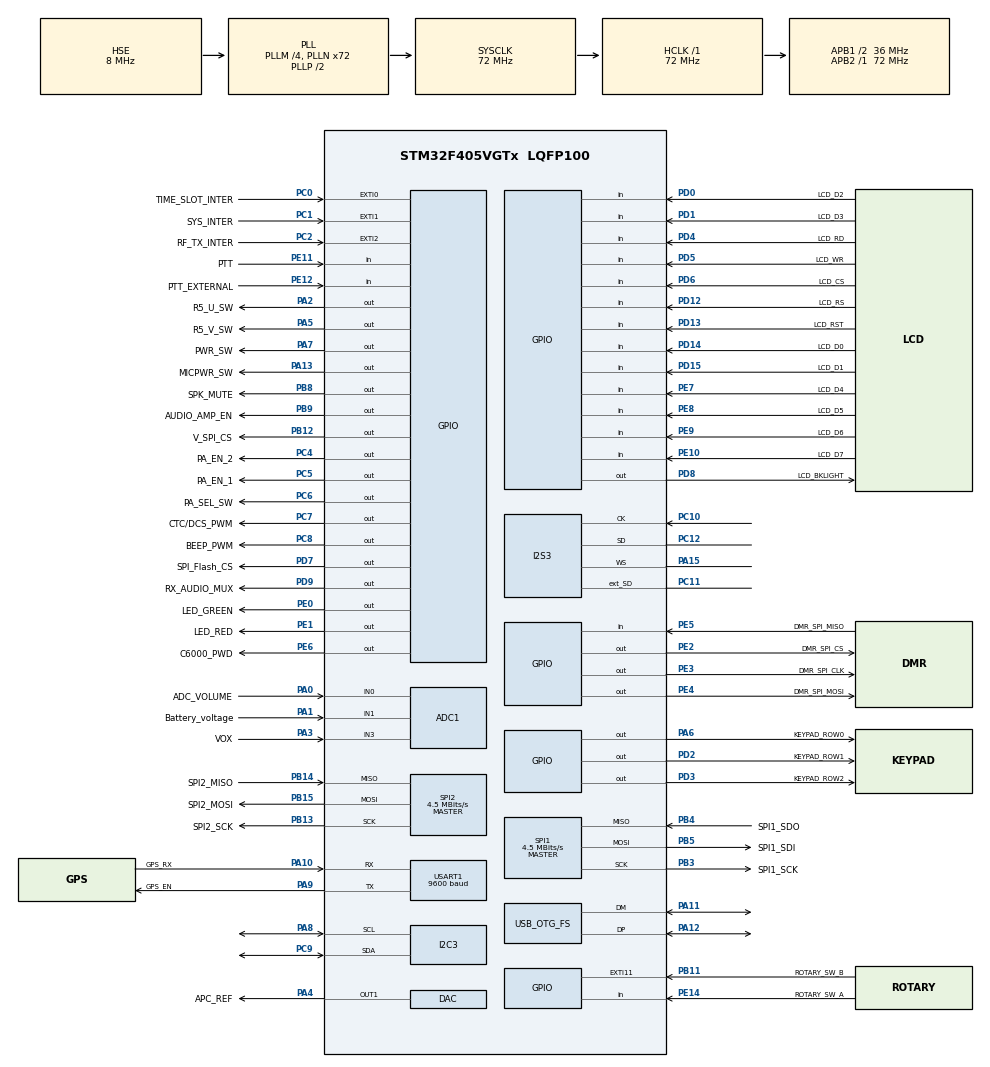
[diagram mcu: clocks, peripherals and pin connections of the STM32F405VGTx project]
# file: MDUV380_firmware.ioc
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ADC1.Channel-0\#ChannelRegularConversion=ADC_CHANNEL_0
ADC1.Channel-1\#ChannelRegularConversion=ADC_CHANNEL_1
ADC1.Channel-2\#ChannelRegularConversion=ADC_CHANNEL_3
ADC1.Channel-3\#ChannelRegularConversion=ADC_CHANNEL_TEMPSENSOR
ADC1.ClockPrescaler=ADC_CLOCK_SYNC_PCLK_DIV8
ADC1.ContinuousConvMode=DISABLE
ADC1.DMAContinuousRequests=ENABLE
ADC1.DiscontinuousConvMode=DISABLE
ADC1.ExternalTrigConv=ADC_EXTERNALTRIGCONV_T3_TRGO
ADC1.InjNumberOfConversion=0
ADC1.NbrOfConversion=4
ADC1.NbrOfConversionFlag=1
ADC1.Rank-0\#ChannelRegularConversion=1
ADC1.Rank-1\#ChannelRegularConversion=2
ADC1.Rank-2\#ChannelRegularConversion=3
ADC1.Rank-3\#ChannelRegularConversion=4
ADC1.SamplingTime-0\#ChannelRegularConversion=ADC_SAMPLETIME_480CYCLES
ADC1.SamplingTime-1\#ChannelRegularConversion=ADC_SAMPLETIME_480CYCLES
ADC1.SamplingTime-2\#ChannelRegularConversion=ADC_SAMPLETIME_480CYCLES
ADC1.SamplingTime-3\#ChannelRegularConversion=ADC_SAMPLETIME_480CYCLES
ADC1.ScanConvMode=ENABLE
ADC1.master=1
Dma.ADC1.5.Direction=DMA_PERIPH_TO_MEMORY
Dma.ADC1.5.FIFOMode=DMA_FIFOMODE_DISABLE
Dma.ADC1.5.Instance=DMA2_Stream4
Dma.ADC1.5.MemDataAlignment=DMA_MDATAALIGN_HALFWORD
Dma.ADC1.5.MemInc=DMA_MINC_ENABLE
Dma.ADC1.5.Mode=DMA_CIRCULAR
Dma.ADC1.5.PeriphDataAlignment=DMA_PDATAALIGN_HALFWORD
Dma.ADC1.5.PeriphInc=DMA_PINC_DISABLE
Dma.ADC1.5.Priority=DMA_PRIORITY_LOW
Dma.I2S3_EXT_TX.0.Direction=DMA_MEMORY_TO_PERIPH
Dma.I2S3_EXT_TX.0.FIFOMode=DMA_FIFOMODE_DISABLE
Dma.I2S3_EXT_TX.0.Instance=DMA1_Stream5
Dma.I2S3_EXT_TX.0.MemDataAlignment=DMA_MDATAALIGN_HALFWORD
Dma.I2S3_EXT_TX.0.MemInc=DMA_MINC_ENABLE
Dma.I2S3_EXT_TX.0.Mode=DMA_CIRCULAR
Dma.I2S3_EXT_TX.0.PeriphDataAlignment=DMA_PDATAALIGN_HALFWORD
Dma.I2S3_EXT_TX.0.PeriphInc=DMA_PINC_DISABLE
Dma.I2S3_EXT_TX.0.Priority=DMA_PRIORITY_LOW
Dma.MEMTOMEM.3.Direction=DMA_MEMORY_TO_MEMORY
Dma.MEMTOMEM.3.FIFOMode=DMA_FIFOMODE_ENABLE
Dma.MEMTOMEM.3.FIFOThreshold=DMA_FIFO_THRESHOLD_FULL
Dma.MEMTOMEM.3.Instance=DMA2_Stream0
Dma.MEMTOMEM.3.MemBurst=DMA_MBURST_SINGLE
Dma.MEMTOMEM.3.MemDataAlignment=DMA_MDATAALIGN_BYTE
Dma.MEMTOMEM.3.MemInc=DMA_MINC_DISABLE
Dma.MEMTOMEM.3.Mode=DMA_NORMAL
Dma.MEMTOMEM.3.PeriphBurst=DMA_PBURST_SINGLE
Dma.MEMTOMEM.3.PeriphDataAlignment=DMA_PDATAALIGN_BYTE
Dma.MEMTOMEM.3.PeriphInc=DMA_PINC_ENABLE
Dma.MEMTOMEM.3.Priority=DMA_PRIORITY_LOW
Dma.Request0=I2S3_EXT_TX
Dma.Request1=SPI3_RX
Dma.Request2=USART1_RX
Dma.Request3=MEMTOMEM
Dma.Request4=TIM1_CH1
Dma.Request5=ADC1
Dma.SPI3_RX.1.Direction=DMA_PERIPH_TO_MEMORY
Dma.SPI3_RX.1.FIFOMode=DMA_FIFOMODE_DISABLE
Dma.SPI3_RX.1.Instance=DMA1_Stream0
Dma.SPI3_RX.1.MemDataAlignment=DMA_MDATAALIGN_HALFWORD
Dma.SPI3_RX.1.MemInc=DMA_MINC_ENABLE
Dma.SPI3_RX.1.Mode=DMA_CIRCULAR
Dma.SPI3_RX.1.PeriphDataAlignment=DMA_PDATAALIGN_HALFWORD
Dma.SPI3_RX.1.PeriphInc=DMA_PINC_DISABLE
Dma.SPI3_RX.1.Priority=DMA_PRIORITY_LOW
Dma.TIM1_CH1.4.Direction=DMA_MEMORY_TO_PERIPH
Dma.TIM1_CH1.4.FIFOMode=DMA_FIFOMODE_DISABLE
Dma.TIM1_CH1.4.Instance=DMA2_Stream1
Dma.TIM1_CH1.4.MemDataAlignment=DMA_MDATAALIGN_WORD
Dma.TIM1_CH1.4.MemInc=DMA_MINC_ENABLE
Dma.TIM1_CH1.4.Mode=DMA_CIRCULAR
Dma.TIM1_CH1.4.PeriphDataAlignment=DMA_PDATAALIGN_WORD
Dma.TIM1_CH1.4.PeriphInc=DMA_PINC_DISABLE
Dma.TIM1_CH1.4.Priority=DMA_PRIORITY_HIGH
Dma.USART1_RX.2.Direction=DMA_PERIPH_TO_MEMORY
Dma.USART1_RX.2.FIFOMode=DMA_FIFOMODE_DISABLE
Dma.USART1_RX.2.Instance=DMA2_Stream2
Dma.USART1_RX.2.MemDataAlignment=DMA_MDATAALIGN_BYTE
Dma.USART1_RX.2.MemInc=DMA_MINC_ENABLE
Dma.USART1_RX.2.Mode=DMA_CIRCULAR
Dma.USART1_RX.2.PeriphDataAlignment=DMA_PDATAALIGN_BYTE
Dma.USART1_RX.2.PeriphInc=DMA_PINC_DISABLE
Dma.USART1_RX.2.Priority=DMA_PRIORITY_LOW
FREERTOS.Tasks01=defaultTask,24,2048,StartDefaultTask,Default,NULL,Dynamic,NULL,NULL
FREERTOS.configLIBRARY_MAX_SYSCALL_INTERRUPT_PRIORITY=5
FREERTOS.configTIMER_TASK_PRIORITY=55
FREERTOS.configTOTAL_HEAP_SIZE=20480
FREERTOS.configUSE_NEWLIB_REENTRANT=1
I2C3.I2C_Mode=I2C_Fast
I2S3.AudioFreq=I2S_AUDIOFREQ_8K
I2S3.CPOL=I2S_CPOL_HIGH
I2S3.DataFormat=I2S_DATAFORMAT_16B_EXTENDED
I2S3.ErrorAudioFreq=-0.27 %
I2S3.FullDuplexMode=I2S_FULLDUPLEXMODE_ENABLE
I2S3.Instance=SPI$Index
I2S3.Mode=I2S_MODE_SLAVE_RX
I2S3.RealAudioFreq=7.978 KHz
I2S3.Standard=I2S_STANDARD_PHILIPS
I2S3.VirtualMode=I2S_MODE_SLAVE
Mcu.Family=STM32F4
Mcu.Name=STM32F405VGTx
Mcu.Package=LQFP100
NVIC.DMA1_Stream0_IRQn=true\:6\:0\:true\:false\:true\:true\:false\:true\:true
NVIC.DMA1_Stream5_IRQn=true\:6\:0\:true\:false\:true\:true\:false\:true\:true
NVIC.DMA2_Stream1_IRQn=true\:15\:0\:true\:false\:true\:true\:false\:true\:true
NVIC.DMA2_Stream2_IRQn=true\:15\:0\:true\:false\:true\:true\:false\:true\:true
NVIC.DMA2_Stream4_IRQn=true\:15\:0\:true\:false\:true\:true\:false\:true\:true
NVIC.EXTI0_IRQn=true\:5\:0\:false\:false\:true\:true\:true\:true\:true
NVIC.EXTI15_10_IRQn=true\:6\:0\:true\:false\:true\:true\:true\:true\:true
NVIC.EXTI1_IRQn=true\:5\:0\:false\:false\:true\:true\:true\:true\:true
NVIC.EXTI2_IRQn=true\:5\:0\:false\:false\:true\:true\:true\:true\:true
NVIC.OTG_FS_IRQn=true\:6\:0\:true\:false\:true\:true\:false\:true\:true
NVIC.PriorityGroup=NVIC_PRIORITYGROUP_4
NVIC.TIM8_TRG_COM_TIM14_IRQn=true\:4\:0\:true\:false\:true\:false\:false\:true\:true
NVIC.TimeBase=TIM8_TRG_COM_TIM14_IRQn
NVIC.TimeBaseIP=TIM14
NVIC.USART1_IRQn=true\:6\:0\:true\:false\:true\:true\:true\:true\:true
PA0-WKUP.GPIO_Label=ADC_VOLUME
PA0-WKUP.Signal=ADCx_IN0
PA1.GPIO_Label=Battery_voltage
PA1.Signal=ADCx_IN1
PA10.GPIO_Label=GPS_RX
PA10.Mode=Asynchronous
PA10.Signal=USART1_RX
PA11.Mode=Device_Only
PA11.Signal=USB_OTG_FS_DM
PA12.Mode=Device_Only
PA12.Signal=USB_OTG_FS_DP
PA13.GPIO_Label=MICPWR_SW
PA13.Signal=GPIO_Output
PA14.Signal=SYS_JTCK-SWCLK
PA15.Mode=Full_Duplex_Slave
PA15.Signal=I2S3_WS
PA2.GPIO_Label=R5_U_SW
PA2.Signal=GPIO_Output
PA3.GPIO_Label=VOX
PA3.Signal=ADCx_IN3
PA4.GPIO_Label=APC_REF
PA4.Signal=COMP_DAC1_group
PA5.GPIO_Label=R5_V_SW
PA5.Signal=GPIO_Output
PA6.GPIO_Label=KEYPAD_ROW0
PA6.Signal=GPIO_Output
PA7.GPIO_Label=PWR_SW
PA7.Signal=GPIO_Output
PA8.Mode=I2C
PA8.Signal=I2C3_SCL
PA9.GPIO_Label=GPS_EN
PA9.Mode=Asynchronous
PA9.Signal=USART1_TX
PB11.GPIO_Label=ROTARY_SW_B
PB11.GPIO_ModeDefaultEXTI=GPIO_MODE_IT_RISING_FALLING
PB11.GPIO_PuPd=GPIO_PULLUP
PB11.Signal=GPXTI11
PB12.GPIO_Label=V_SPI_CS
PB12.PinState=GPIO_PIN_SET
PB12.Signal=GPIO_Output
PB13.GPIO_Label=SPI2_SCK
PB13.Mode=Full_Duplex_Master
PB13.Signal=SPI2_SCK
PB14.GPIO_Label=SPI2_MISO
PB14.Mode=Full_Duplex_Master
PB14.Signal=SPI2_MISO
PB15.GPIO_Label=SPI2_MOSI
PB15.Mode=Full_Duplex_Master
PB15.Signal=SPI2_MOSI
PB3.GPIO_Label=SPI1_SCK
PB3.Mode=Full_Duplex_Master
PB3.Signal=SPI1_SCK
PB4.GPIO_Label=SPI1_SDO
PB4.Mode=Full_Duplex_Master
PB4.Signal=SPI1_MISO
PB5.GPIO_Label=SPI1_SDI
PB5.Mode=Full_Duplex_Master
PB5.Signal=SPI1_MOSI
PB8.GPIO_Label=SPK_MUTE
PB8.PinState=GPIO_PIN_SET
PB8.Signal=GPIO_Output
PB9.GPIO_Label=AUDIO_AMP_EN
PB9.PinState=GPIO_PIN_SET
PB9.Signal=GPIO_Output
PC0.GPIO_Label=TIME_SLOT_INTER
PC0.GPIO_ModeDefaultEXTI=GPIO_MODE_IT_FALLING
PC0.Signal=GPXTI0
PC1.GPIO_Label=SYS_INTER
PC1.GPIO_ModeDefaultEXTI=GPIO_MODE_IT_FALLING
PC1.Signal=GPXTI1
PC10.Mode=Full_Duplex_Slave
PC10.Signal=I2S3_CK
PC11.Mode=Full_Duplex_Slave
PC11.Signal=I2S3_ext_SD
PC12.Mode=Full_Duplex_Slave
PC12.Signal=I2S3_SD
PC14-OSC32_IN.Mode=LSE-External-Oscillator
PC14-OSC32_IN.Signal=RCC_OSC32_IN
PC15-OSC32_OUT.Mode=LSE-External-Oscillator
PC15-OSC32_OUT.Signal=RCC_OSC32_OUT
PC2.GPIO_Label=RF_TX_INTER
PC2.GPIO_ModeDefaultEXTI=GPIO_MODE_IT_FALLING
PC2.Signal=GPXTI2
PC4.GPIO_Label=PA_EN_2
PC4.Signal=GPIO_Output
PC5.GPIO_Label=PA_EN_1
PC5.Signal=GPIO_Output
PC6.GPIO_Label=PA_SEL_SW
PC6.Signal=GPIO_Output
PC7.GPIO_Label=CTC/DCS_PWM
PC7.GPIO_ModeDefaultOutputPP=GPIO_MODE_OUTPUT_OD
PC7.PinState=GPIO_PIN_SET
PC7.Signal=GPIO_Output
PC8.GPIO_Label=BEEP_PWM
PC8.Signal=GPIO_Output
PC9.Mode=I2C
PC9.Signal=I2C3_SDA
PD0.GPIO_Label=LCD_D2
PD0.GPIO_PuPd=GPIO_PULLDOWN
PD0.Signal=GPIO_Input
PD1.GPIO_Label=LCD_D3
PD1.GPIO_PuPd=GPIO_PULLDOWN
PD1.Signal=GPIO_Input
PD12.GPIO_Label=LCD_RS
PD12.Signal=GPIO_Input
PD13.GPIO_Label=LCD_RST
PD13.Signal=GPIO_Input
PD14.GPIO_Label=LCD_D0
PD14.GPIO_PuPd=GPIO_PULLDOWN
PD14.Signal=GPIO_Input
PD15.GPIO_Label=LCD_D1
PD15.GPIO_PuPd=GPIO_PULLDOWN
PD15.Signal=GPIO_Input
PD2.GPIO_Label=KEYPAD_ROW1
PD2.Signal=GPIO_Output
PD3.GPIO_Label=KEYPAD_ROW2
PD3.Signal=GPIO_Output
PD4.GPIO_Label=LCD_RD
PD4.Signal=GPIO_Input
PD5.GPIO_Label=LCD_WR
PD5.Signal=GPIO_Input
PD6.GPIO_Label=LCD_CS
PD6.Signal=GPIO_Input
PD7.GPIO_Label=SPI_Flash_CS
PD7.GPIO_Speed=GPIO_SPEED_FREQ_LOW
PD7.PinState=GPIO_PIN_SET
PD7.Signal=GPIO_Output
PD8.GPIO_Label=LCD_BKLIGHT
PD8.Signal=GPIO_Output
PD9.GPIO_Label=RX_AUDIO_MUX
PD9.PinState=GPIO_PIN_SET
PD9.Signal=GPIO_Output
PE0.GPIO_Label=LED_GREEN
PE0.Signal=GPIO_Output
PE1.GPIO_Label=LED_RED
PE1.Signal=GPIO_Output
PE10.GPIO_Label=LCD_D7
PE10.GPIO_PuPd=GPIO_PULLDOWN
PE10.Signal=GPIO_Input
PE11.GPIO_Label=PTT
PE11.GPIO_PuPd=GPIO_PULLUP
PE11.Signal=GPIO_Input
PE12.GPIO_Label=PTT_EXTERNAL
PE12.GPIO_PuPd=GPIO_PULLUP
PE12.Signal=GPIO_Input
PE14.GPIO_Label=ROTARY_SW_A
PE14.GPIO_PuPd=GPIO_PULLUP
PE14.Signal=GPIO_Input
PE2.GPIO_Label=DMR_SPI_CS
PE2.PinState=GPIO_PIN_SET
PE2.Signal=GPIO_Output
PE3.GPIO_Label=DMR_SPI_CLK
PE3.Signal=GPIO_Output
PE4.GPIO_Label=DMR_SPI_MOSI
PE4.Signal=GPIO_Output
PE5.GPIO_Label=DMR_SPI_MISO
PE5.Signal=GPIO_Input
PE6.GPIO_Label=C6000_PWD
PE6.PinState=GPIO_PIN_SET
PE6.Signal=GPIO_Output
PE7.GPIO_Label=LCD_D4
PE7.GPIO_PuPd=GPIO_PULLDOWN
PE7.Signal=GPIO_Input
PE8.GPIO_Label=LCD_D5
PE8.GPIO_PuPd=GPIO_PULLDOWN
PE8.Signal=GPIO_Input
PE9.GPIO_Label=LCD_D6
PE9.GPIO_PuPd=GPIO_PULLDOWN
PE9.Signal=GPIO_Input
PH0-OSC_IN.Mode=HSE-External-Clock-Source
PH0-OSC_IN.Signal=RCC_OSC_IN
PH1-OSC_OUT.Mode=HSE-External-Clock-Source
PH1-OSC_OUT.Signal=RCC_OSC_OUT
ProjectManager.HeapSize=0x200
ProjectManager.StackSize=0x400
ProjectManager.TargetToolchain=STM32CubeIDE
RCC.48MHZClocksFreq_Value=48000000
RCC.AHBFreq_Value=72000000
RCC.APB1CLKDivider=RCC_HCLK_DIV2
RCC.APB1Freq_Value=36000000
RCC.APB1TimFreq_Value=72000000
RCC.APB2Freq_Value=72000000
RCC.APB2TimFreq_Value=72000000
RCC.CortexFreq_Value=72000000
RCC.HCLKFreq_Value=72000000
RCC.HSE_VALUE=8000000
RCC.HSI_VALUE=16000000
RCC.PLLI2SR=4
RCC.PLLM=4
RCC.PLLN=72
RCC.PLLQ=3
RCC.RCC_RTC_Clock_Source=RCC_RTCCLKSOURCE_LSE
RCC.RCC_RTC_Clock_SourceVirtual=RCC_RTCCLKSOURCE_LSE
RCC.SYSCLKFreq_VALUE=72000000
RCC.SYSCLKSource=RCC_SYSCLKSOURCE_PLLCLK
RCC.VCOOutputFreq_Value=144000000
SH.ADCx_IN0.0=ADC1_IN0,IN0
SH.ADCx_IN1.0=ADC1_IN1,IN1
SH.ADCx_IN3.0=ADC1_IN3,IN3
SH.COMP_DAC1_group.0=DAC_OUT1,DAC_OUT1
SPI1.BaudRatePrescaler=SPI_BAUDRATEPRESCALER_16
SPI1.CLKPolarity=SPI_POLARITY_LOW
SPI1.CalculateBaudRate=4.5 MBits/s
SPI1.Direction=SPI_DIRECTION_2LINES
SPI1.Mode=SPI_MODE_MASTER
SPI1.VirtualType=VM_MASTER
SPI2.BaudRatePrescaler=SPI_BAUDRATEPRESCALER_8
SPI2.CLKPolarity=SPI_POLARITY_HIGH
SPI2.CalculateBaudRate=4.5 MBits/s
SPI2.Direction=SPI_DIRECTION_2LINES
SPI2.Mode=SPI_MODE_MASTER
SPI2.VirtualType=VM_MASTER
TIM1.AutoReloadPreload=TIM_AUTORELOAD_PRELOAD_ENABLE
TIM1.Channel-Output\ Compare1\ No\ Output=TIM_CHANNEL_1
TIM1.OCMode_1=TIM_OCMODE_TIMING
TIM1.Period=7100
TIM1.Prescaler=0
TIM1.TIM_MasterOutputTrigger=TIM_TRGO_UPDATE
TIM2.AutoReloadPreload=TIM_AUTORELOAD_PRELOAD_ENABLE
TIM2.Channel-Output\ Compare4\ No\ Output=TIM_CHANNEL_4
TIM2.Period=1024
TIM2.Prescaler=1024
TIM2.TIM_MasterOutputTrigger=TIM_TRGO_UPDATE
TIM2.TIM_MasterSlaveMode=TIM_MASTERSLAVEMODE_DISABLE
TIM3.AutoReloadPreload=TIM_AUTORELOAD_PRELOAD_ENABLE
TIM3.Channel-Output\ Compare4\ No\ Output=TIM_CHANNEL_4
TIM3.Period=1000
TIM3.Prescaler=1023
TIM3.TIM_MasterOutputTrigger=TIM_TRGO_UPDATE
TIM4.AutoReloadPreload=TIM_AUTORELOAD_PRELOAD_ENABLE
TIM4.Channel-Output\ Compare4\ No\ Output=TIM_CHANNEL_4
TIM4.Period=1000
TIM4.Prescaler=7200
USART1.BaudRate=9600
USART1.Mode=MODE_RX
USART1.VirtualMode=VM_ASYNC
USB_DEVICE.CLASS_NAME_FS=CDC
USB_DEVICE.MANUFACTURER_STRING-CDC_FS=www.opengd77.com
USB_DEVICE.PID_CDC_FS=148
USB_DEVICE.PRODUCT_STRING_CDC_FS=OpenMDUV380 Transceiver
USB_DEVICE.VID-CDC_FS=8137
USB_DEVICE.VirtualMode-CDC_FS=Cdc
USB_DEVICE.VirtualModeFS=Cdc_FS
USB_OTG_FS.VirtualMode=Device_Only
VP_ADC1_TempSens_Input.Mode=IN-TempSens
VP_FREERTOS_VS_CMSIS_V2.Mode=CMSIS_V2
VP_RTC_VS_RTC_Activate.Mode=RTC_Enabled
VP_SYS_VS_tim14.Mode=TIM14
VP_TIM1_VS_ClockSourceINT.Mode=Internal
VP_TIM1_VS_no_output1.Mode=Output Compare1 No Output
VP_TIM2_VS_no_output4.Mode=Output Compare4 No Output
VP_TIM3_VS_ClockSourceINT.Mode=Internal
VP_TIM3_VS_no_output4.Mode=Output Compare4 No Output
VP_TIM4_VS_no_output4.Mode=Output Compare4 No Output
VP_USB_DEVICE_VS_USB_DEVICE_CDC_FS.Mode=CDC_FS
board=custom

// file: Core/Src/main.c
/* USER CODE BEGIN Header */
/**
  ******************************************************************************
  * @file           : main.c
  * @brief          : Main program body
  ******************************************************************************
  * @attention
  *
  * <h2><center>&copy; Copyright (c) 2020 STMicroelectronics.
  * All rights reserved.</center></h2>
  *
  * This software component is licensed by ST under BSD 3-Clause license,
  * the "License"; You may not use this file except in compliance with the
  * License. You may obtain a copy of the License at:
  *                        opensource.org/licenses/BSD-3-Clause
  *
  ******************************************************************************
  */
/* USER CODE END Header */
#include "main.h"
#include "cmsis_os.h"
#include "usb_device.h"
#include "interfaces/usb_com.h"

/* USER CODE BEGIN Includes */
#include "applicationMain.h"
/* USER CODE END Includes */

ADC_HandleTypeDef hadc1;
DMA_HandleTypeDef hdma_adc1;

DAC_HandleTypeDef hdac;

I2C_HandleTypeDef hi2c3;

I2S_HandleTypeDef hi2s3;
DMA_HandleTypeDef hdma_i2s3_ext_tx;
DMA_HandleTypeDef hdma_spi3_rx;

RTC_HandleTypeDef hrtc;

SPI_HandleTypeDef hspi1;
SPI_HandleTypeDef hspi2;

TIM_HandleTypeDef htim1;
TIM_HandleTypeDef htim2;
TIM_HandleTypeDef htim3;
TIM_HandleTypeDef htim4;
DMA_HandleTypeDef hdma_tim1_ch1;

UART_HandleTypeDef huart1;
DMA_HandleTypeDef hdma_usart1_rx;

DMA_HandleTypeDef hdma_memtomem_dma2_stream0;
/* Definitions for defaultTask */
osThreadId_t defaultTaskHandle;
const osThreadAttr_t defaultTask_attributes = {
  .name = "defaultTask",
  .stack_size = 2048 * 4,
  .priority = (osPriority_t) osPriorityNormal,
};

void SystemClock_Config(void);
static void MX_DMA_Init(void);
static void MX_GPIO_Init(void);
static void MX_ADC1_Init(void);
static void MX_I2S3_Init(void);
static void MX_SPI2_Init(void);
static void MX_SPI1_Init(void);
static void MX_RTC_Init(void);
static void MX_USART1_UART_Init(void);
static void MX_DAC_Init(void);
static void MX_I2C3_Init(void);
static void MX_TIM1_Init(void);
static void MX_TIM2_Init(void);
static void MX_TIM4_Init(void);
static void MX_TIM3_Init(void);
void StartDefaultTask(void *argument);

int main(void)
{

  /* MCU Configuration--------------------------------------------------------*/

  /* Reset of all peripherals, Initializes the Flash interface and the Systick. */
  HAL_Init();

  /* USER CODE BEGIN Init */
  __HAL_RCC_SYSCLK_CONFIG(RCC_CFGR_SWS_HSI);//Switch clock to internal, as bootloader already set it to HSE and otherwise HSE can't be configured in SystemClock_Config()
  /* USER CODE END Init */

  /* Configure the system clock */
  SystemClock_Config();

  /* Initialize all configured peripherals */
  MX_DMA_Init();
  MX_GPIO_Init();
  MX_ADC1_Init();
  MX_I2S3_Init();
  MX_SPI2_Init();
  MX_SPI1_Init();
  MX_RTC_Init();
  MX_USART1_UART_Init();
  MX_DAC_Init();
  MX_I2C3_Init();
  MX_TIM1_Init();
  MX_TIM2_Init();
  MX_TIM4_Init();
  MX_TIM3_Init();
  /* USER CODE BEGIN 2 */

	for(int i=0;i<20;i++)
	{
	  nonOSDelay(100);

	  HAL_GPIO_TogglePin(LED_RED_GPIO_Port, LED_RED_Pin);
	}

    HAL_GPIO_WritePin(LED_RED_GPIO_Port, LED_RED_Pin,false);

    MX_USB_DEVICE_Init();
	nonOSDelay(500);

	for(int i=5; i>=0; i--)
	{
		USB_DEBUG_printf("USB Serial %d\n",i);
		nonOSDelay(500);
	}

	displayLCD_Type = SPI_Flash_readSingleSecurityRegister(0x301D);
	displayLCD_Type &= 0x03;

  displayEnableBacklight(true, 100);

  gpioSetDisplayBacklightIntensityPercentage(100);

	displayInit(0x000000, 0xffffff, false);
	gpioInitDisplay();

	displayClearBuf();
	displayPrintCentered(0,"CPU Start", FONT_SIZE_3);
	displayRender();

	nonOSDelay(2000);

  /* USER CODE END 2 */

  /* Init scheduler */
  osKernelInitialize();

	displayPrintCentered(24,"osKernelInitialize", FONT_SIZE_2);
	displayRender();
	nonOSDelay(2000);

  /* Create the thread(s) */
  /* creation of defaultTask */
  defaultTaskHandle = osThreadNew(StartDefaultTask, NULL, &defaultTask_attributes);

	displayPrintCentered(32,"osThreadNew", FONT_SIZE_2);
	displayRender();
	nonOSDelay(2000);

  /* Start scheduler */

  osKernelStart();

  /* We should never get here as control is now taken by the scheduler */
  /* Infinite loop */
  while (1)
  {

  }
}

void SystemClock_Config(void)
{
  RCC_OscInitTypeDef RCC_OscInitStruct = {0};
  RCC_ClkInitTypeDef RCC_ClkInitStruct = {0};

  /** Configure the main internal regulator output voltage
  */
  __HAL_RCC_PWR_CLK_ENABLE();
  __HAL_PWR_VOLTAGESCALING_CONFIG(PWR_REGULATOR_VOLTAGE_SCALE1);

  /** Initializes the RCC Oscillators according to the specified parameters
  * in the RCC_OscInitTypeDef structure.
  */
  RCC_OscInitStruct.OscillatorType = RCC_OSCILLATORTYPE_HSE|RCC_OSCILLATORTYPE_LSE;
  RCC_OscInitStruct.HSEState = RCC_HSE_BYPASS;
  RCC_OscInitStruct.LSEState = RCC_LSE_ON;
  RCC_OscInitStruct.PLL.PLLState = RCC_PLL_ON;
  RCC_OscInitStruct.PLL.PLLSource = RCC_PLLSOURCE_HSE;
  RCC_OscInitStruct.PLL.PLLM = 4;
  RCC_OscInitStruct.PLL.PLLN = 72;
  RCC_OscInitStruct.PLL.PLLP = RCC_PLLP_DIV2;
  RCC_OscInitStruct.PLL.PLLQ = 3;
  if (HAL_RCC_OscConfig(&RCC_OscInitStruct) != HAL_OK)
  {
    Error_Handler();
  }

  /** Initializes the CPU, AHB and APB buses clocks
  */
  RCC_ClkInitStruct.ClockType = RCC_CLOCKTYPE_HCLK|RCC_CLOCKTYPE_SYSCLK
                              |RCC_CLOCKTYPE_PCLK1|RCC_CLOCKTYPE_PCLK2;
  RCC_ClkInitStruct.SYSCLKSource = RCC_SYSCLKSOURCE_PLLCLK;
  RCC_ClkInitStruct.AHBCLKDivider = RCC_SYSCLK_DIV1;
  RCC_ClkInitStruct.APB1CLKDivider = RCC_HCLK_DIV2;
  RCC_ClkInitStruct.APB2CLKDivider = RCC_HCLK_DIV1;

  if (HAL_RCC_ClockConfig(&RCC_ClkInitStruct, FLASH_LATENCY_2) != HAL_OK)
  {
    Error_Handler();
  }
}

static void MX_ADC1_Init(void)
{

  ADC_ChannelConfTypeDef sConfig = {0};

  /** Configure the global features of the ADC (Clock, Resolution, Data Alignment and number of conversion)
  */
  hadc1.Instance = ADC1;
  hadc1.Init.ClockPrescaler = ADC_CLOCK_SYNC_PCLK_DIV8;
  hadc1.Init.Resolution = ADC_RESOLUTION_12B;
  hadc1.Init.ScanConvMode = ENABLE;
  hadc1.Init.ContinuousConvMode = DISABLE;
  hadc1.Init.DiscontinuousConvMode = DISABLE;
  hadc1.Init.ExternalTrigConvEdge = ADC_EXTERNALTRIGCONVEDGE_RISING;
  hadc1.Init.ExternalTrigConv = ADC_EXTERNALTRIGCONV_T3_TRGO;
  hadc1.Init.DataAlign = ADC_DATAALIGN_RIGHT;
  hadc1.Init.NbrOfConversion = 4;
  hadc1.Init.DMAContinuousRequests = ENABLE;
  hadc1.Init.EOCSelection = ADC_EOC_SINGLE_CONV;
  if (HAL_ADC_Init(&hadc1) != HAL_OK)
  {
    Error_Handler();
  }

  /** Configure for the selected ADC regular channel its corresponding rank in the sequencer and its sample time.
  */
  sConfig.Channel = ADC_CHANNEL_0;
  sConfig.Rank = 1;
  sConfig.SamplingTime = ADC_SAMPLETIME_480CYCLES;
  if (HAL_ADC_ConfigChannel(&hadc1, &sConfig) != HAL_OK)
  {
    Error_Handler();
  }

  /** Configure for the selected ADC regular channel its corresponding rank in the sequencer and its sample time.
  */
  sConfig.Channel = ADC_CHANNEL_1;
  sConfig.Rank = 2;
  if (HAL_ADC_ConfigChannel(&hadc1, &sConfig) != HAL_OK)
  {
    Error_Handler();
  }

  /** Configure for the selected ADC regular channel its corresponding rank in the sequencer and its sample time.
  */
  sConfig.Channel = ADC_CHANNEL_3;
  sConfig.Rank = 3;
  if (HAL_ADC_ConfigChannel(&hadc1, &sConfig) != HAL_OK)
  {
    Error_Handler();
  }

  /** Configure for the selected ADC regular channel its corresponding rank in the sequencer and its sample time.
  */
  sConfig.Channel = ADC_CHANNEL_TEMPSENSOR;
  sConfig.Rank = 4;
  if (HAL_ADC_ConfigChannel(&hadc1, &sConfig) != HAL_OK)
  {
    Error_Handler();
  }

}

static void MX_DAC_Init(void)
{

  DAC_ChannelConfTypeDef sConfig = {0};

  /** DAC Initialization
  */
  hdac.Instance = DAC;
  if (HAL_DAC_Init(&hdac) != HAL_OK)
  {
    Error_Handler();
  }

  /** DAC channel OUT1 config
  */
  sConfig.DAC_Trigger = DAC_TRIGGER_NONE;
  sConfig.DAC_OutputBuffer = DAC_OUTPUTBUFFER_ENABLE;
  if (HAL_DAC_ConfigChannel(&hdac, &sConfig, DAC_CHANNEL_1) != HAL_OK)
  {
    Error_Handler();
  }

}

static void MX_I2C3_Init(void)
{

  hi2c3.Instance = I2C3;
  hi2c3.Init.ClockSpeed = 400000;
  hi2c3.Init.DutyCycle = I2C_DUTYCYCLE_2;
  hi2c3.Init.OwnAddress1 = 0;
  hi2c3.Init.AddressingMode = I2C_ADDRESSINGMODE_7BIT;
  hi2c3.Init.DualAddressMode = I2C_DUALADDRESS_DISABLE;
  hi2c3.Init.OwnAddress2 = 0;
  hi2c3.Init.GeneralCallMode = I2C_GENERALCALL_DISABLE;
  hi2c3.Init.NoStretchMode = I2C_NOSTRETCH_DISABLE;
  if (HAL_I2C_Init(&hi2c3) != HAL_OK)
  {
    Error_Handler();
  }

}

static void MX_I2S3_Init(void)
{

  hi2s3.Instance = SPI3;
  hi2s3.Init.Mode = I2S_MODE_SLAVE_RX;
  hi2s3.Init.Standard = I2S_STANDARD_PHILIPS;
  hi2s3.Init.DataFormat = I2S_DATAFORMAT_16B_EXTENDED;
  hi2s3.Init.MCLKOutput = I2S_MCLKOUTPUT_DISABLE;
  hi2s3.Init.AudioFreq = I2S_AUDIOFREQ_8K;
  hi2s3.Init.CPOL = I2S_CPOL_HIGH;
  hi2s3.Init.ClockSource = I2S_CLOCK_PLL;
  hi2s3.Init.FullDuplexMode = I2S_FULLDUPLEXMODE_ENABLE;
  if (HAL_I2S_Init(&hi2s3) != HAL_OK)
  {
    Error_Handler();
  }

}

static void MX_RTC_Init(void)
{

  /** Initialize RTC Only
  */
  hrtc.Instance = RTC;
  hrtc.Init.HourFormat = RTC_HOURFORMAT_24;
  hrtc.Init.AsynchPrediv = 127;
  hrtc.Init.SynchPrediv = 255;
  hrtc.Init.OutPut = RTC_OUTPUT_DISABLE;
  hrtc.Init.OutPutPolarity = RTC_OUTPUT_POLARITY_HIGH;
  hrtc.Init.OutPutType = RTC_OUTPUT_TYPE_OPENDRAIN;
  if (HAL_RTC_Init(&hrtc) != HAL_OK)
  {
    Error_Handler();
  }

}

static void MX_SPI1_Init(void)
{

  /* SPI1 parameter configuration*/
  hspi1.Instance = SPI1;
  hspi1.Init.Mode = SPI_MODE_MASTER;
  hspi1.Init.Direction = SPI_DIRECTION_2LINES;
  hspi1.Init.DataSize = SPI_DATASIZE_8BIT;
  hspi1.Init.CLKPolarity = SPI_POLARITY_LOW;
  hspi1.Init.CLKPhase = SPI_PHASE_1EDGE;
  hspi1.Init.NSS = SPI_NSS_SOFT;
  hspi1.Init.BaudRatePrescaler = SPI_BAUDRATEPRESCALER_16;
  hspi1.Init.FirstBit = SPI_FIRSTBIT_MSB;
  hspi1.Init.TIMode = SPI_TIMODE_DISABLE;
  hspi1.Init.CRCCalculation = SPI_CRCCALCULATION_DISABLE;
  hspi1.Init.CRCPolynomial = 10;
  if (HAL_SPI_Init(&hspi1) != HAL_OK)
  {
    Error_Handler();
  }

}

static void MX_SPI2_Init(void)
{

  /* SPI2 parameter configuration*/
  hspi2.Instance = SPI2;
  hspi2.Init.Mode = SPI_MODE_MASTER;
  hspi2.Init.Direction = SPI_DIRECTION_2LINES;
  hspi2.Init.DataSize = SPI_DATASIZE_8BIT;
  hspi2.Init.CLKPolarity = SPI_POLARITY_HIGH;
  hspi2.Init.CLKPhase = SPI_PHASE_1EDGE;
  hspi2.Init.NSS = SPI_NSS_SOFT;
  hspi2.Init.BaudRatePrescaler = SPI_BAUDRATEPRESCALER_8;
  hspi2.Init.FirstBit = SPI_FIRSTBIT_MSB;
  hspi2.Init.TIMode = SPI_TIMODE_DISABLE;
  hspi2.Init.CRCCalculation = SPI_CRCCALCULATION_DISABLE;
  hspi2.Init.CRCPolynomial = 10;
  if (HAL_SPI_Init(&hspi2) != HAL_OK)
  {
    Error_Handler();
  }

}

static void MX_TIM1_Init(void)
{

  TIM_ClockConfigTypeDef sClockSourceConfig = {0};
  TIM_MasterConfigTypeDef sMasterConfig = {0};
  TIM_OC_InitTypeDef sConfigOC = {0};
  TIM_BreakDeadTimeConfigTypeDef sBreakDeadTimeConfig = {0};

  htim1.Instance = TIM1;
  htim1.Init.Prescaler = 0;
  htim1.Init.CounterMode = TIM_COUNTERMODE_UP;
  htim1.Init.Period = 7100;
  htim1.Init.ClockDivision = TIM_CLOCKDIVISION_DIV1;
  htim1.Init.RepetitionCounter = 0;
  htim1.Init.AutoReloadPreload = TIM_AUTORELOAD_PRELOAD_ENABLE;
  if (HAL_TIM_Base_Init(&htim1) != HAL_OK)
  {
    Error_Handler();
  }
  sClockSourceConfig.ClockSource = TIM_CLOCKSOURCE_INTERNAL;
  if (HAL_TIM_ConfigClockSource(&htim1, &sClockSourceConfig) != HAL_OK)
  {
    Error_Handler();
  }
  if (HAL_TIM_OC_Init(&htim1) != HAL_OK)
  {
    Error_Handler();
  }
  sMasterConfig.MasterOutputTrigger = TIM_TRGO_UPDATE;
  sMasterConfig.MasterSlaveMode = TIM_MASTERSLAVEMODE_DISABLE;
  if (HAL_TIMEx_MasterConfigSynchronization(&htim1, &sMasterConfig) != HAL_OK)
  {
    Error_Handler();
  }
  sConfigOC.OCMode = TIM_OCMODE_TIMING;
  sConfigOC.Pulse = 0;
  sConfigOC.OCPolarity = TIM_OCPOLARITY_HIGH;
  sConfigOC.OCNPolarity = TIM_OCNPOLARITY_HIGH;
  sConfigOC.OCFastMode = TIM_OCFAST_DISABLE;
  sConfigOC.OCIdleState = TIM_OCIDLESTATE_RESET;
  sConfigOC.OCNIdleState = TIM_OCNIDLESTATE_RESET;
  if (HAL_TIM_OC_ConfigChannel(&htim1, &sConfigOC, TIM_CHANNEL_1) != HAL_OK)
  {
    Error_Handler();
  }
  sBreakDeadTimeConfig.OffStateRunMode = TIM_OSSR_DISABLE;
  sBreakDeadTimeConfig.OffStateIDLEMode = TIM_OSSI_DISABLE;
  sBreakDeadTimeConfig.LockLevel = TIM_LOCKLEVEL_OFF;
  sBreakDeadTimeConfig.DeadTime = 0;
  sBreakDeadTimeConfig.BreakState = TIM_BREAK_DISABLE;
  sBreakDeadTimeConfig.BreakPolarity = TIM_BREAKPOLARITY_HIGH;
  sBreakDeadTimeConfig.AutomaticOutput = TIM_AUTOMATICOUTPUT_DISABLE;
  if (HAL_TIMEx_ConfigBreakDeadTime(&htim1, &sBreakDeadTimeConfig) != HAL_OK)
  {
    Error_Handler();
  }

}

static void MX_TIM2_Init(void)
{

  TIM_MasterConfigTypeDef sMasterConfig = {0};
  TIM_OC_InitTypeDef sConfigOC = {0};

  htim2.Instance = TIM2;
  htim2.Init.Prescaler = 1024;
  htim2.Init.CounterMode = TIM_COUNTERMODE_UP;
  htim2.Init.Period = 1024;
  htim2.Init.ClockDivision = TIM_CLOCKDIVISION_DIV1;
  htim2.Init.AutoReloadPreload = TIM_AUTORELOAD_PRELOAD_ENABLE;
  if (HAL_TIM_OC_Init(&htim2) != HAL_OK)
  {
    Error_Handler();
  }
  sMasterConfig.MasterOutputTrigger = TIM_TRGO_UPDATE;
  sMasterConfig.MasterSlaveMode = TIM_MASTERSLAVEMODE_DISABLE;
  if (HAL_TIMEx_MasterConfigSynchronization(&htim2, &sMasterConfig) != HAL_OK)
  {
    Error_Handler();
  }
  sConfigOC.OCMode = TIM_OCMODE_TIMING;
  sConfigOC.Pulse = 0;
  sConfigOC.OCPolarity = TIM_OCPOLARITY_HIGH;
  sConfigOC.OCFastMode = TIM_OCFAST_DISABLE;
  if (HAL_TIM_OC_ConfigChannel(&htim2, &sConfigOC, TIM_CHANNEL_4) != HAL_OK)
  {
    Error_Handler();
  }

}

static void MX_TIM3_Init(void)
{

  TIM_ClockConfigTypeDef sClockSourceConfig = {0};
  TIM_MasterConfigTypeDef sMasterConfig = {0};
  TIM_OC_InitTypeDef sConfigOC = {0};

  htim3.Instance = TIM3;
  htim3.Init.Prescaler = 1023;
  htim3.Init.CounterMode = TIM_COUNTERMODE_UP;
  htim3.Init.Period = 1000;
  htim3.Init.ClockDivision = TIM_CLOCKDIVISION_DIV1;
  htim3.Init.AutoReloadPreload = TIM_AUTORELOAD_PRELOAD_ENABLE;
  if (HAL_TIM_Base_Init(&htim3) != HAL_OK)
  {
    Error_Handler();
  }
  sClockSourceConfig.ClockSource = TIM_CLOCKSOURCE_INTERNAL;
  if (HAL_TIM_ConfigClockSource(&htim3, &sClockSourceConfig) != HAL_OK)
  {
    Error_Handler();
  }
  if (HAL_TIM_OC_Init(&htim3) != HAL_OK)
  {
    Error_Handler();
  }
  sMasterConfig.MasterOutputTrigger = TIM_TRGO_UPDATE;
  sMasterConfig.MasterSlaveMode = TIM_MASTERSLAVEMODE_DISABLE;
  if (HAL_TIMEx_MasterConfigSynchronization(&htim3, &sMasterConfig) != HAL_OK)
  {
    Error_Handler();
  }
  sConfigOC.OCMode = TIM_OCMODE_TIMING;
  sConfigOC.Pulse = 0;
  sConfigOC.OCPolarity = TIM_OCPOLARITY_HIGH;
  sConfigOC.OCFastMode = TIM_OCFAST_DISABLE;
  if (HAL_TIM_OC_ConfigChannel(&htim3, &sConfigOC, TIM_CHANNEL_4) != HAL_OK)
  {
    Error_Handler();
  }

}

static void MX_TIM4_Init(void)
{

  TIM_MasterConfigTypeDef sMasterConfig = {0};
  TIM_OC_InitTypeDef sConfigOC = {0};

  htim4.Instance = TIM4;
  htim4.Init.Prescaler = 7200;
  htim4.Init.CounterMode = TIM_COUNTERMODE_UP;
  htim4.Init.Period = 1000;
  htim4.Init.ClockDivision = TIM_CLOCKDIVISION_DIV1;
  htim4.Init.AutoReloadPreload = TIM_AUTORELOAD_PRELOAD_ENABLE;
  if (HAL_TIM_OC_Init(&htim4) != HAL_OK)
  {
    Error_Handler();
  }
  sMasterConfig.MasterOutputTrigger = TIM_TRGO_RESET;
  sMasterConfig.MasterSlaveMode = TIM_MASTERSLAVEMODE_DISABLE;
  if (HAL_TIMEx_MasterConfigSynchronization(&htim4, &sMasterConfig) != HAL_OK)
  {
    Error_Handler();
  }
  sConfigOC.OCMode = TIM_OCMODE_TIMING;
  sConfigOC.Pulse = 0;
  sConfigOC.OCPolarity = TIM_OCPOLARITY_HIGH;
  sConfigOC.OCFastMode = TIM_OCFAST_DISABLE;
  if (HAL_TIM_OC_ConfigChannel(&htim4, &sConfigOC, TIM_CHANNEL_4) != HAL_OK)
  {
    Error_Handler();
  }

}

static void MX_USART1_UART_Init(void)
{

  huart1.Instance = USART1;
  huart1.Init.BaudRate = 9600;
  huart1.Init.WordLength = UART_WORDLENGTH_8B;
  huart1.Init.StopBits = UART_STOPBITS_1;
  huart1.Init.Parity = UART_PARITY_NONE;
  huart1.Init.Mode = UART_MODE_RX;
  huart1.Init.HwFlowCtl = UART_HWCONTROL_NONE;
  huart1.Init.OverSampling = UART_OVERSAMPLING_16;
  if (HAL_UART_Init(&huart1) != HAL_OK)
  {
    Error_Handler();
  }

}

static void MX_DMA_Init(void)
{

  /* DMA controller clock enable */
  __HAL_RCC_DMA1_CLK_ENABLE();
  __HAL_RCC_DMA2_CLK_ENABLE();

  /* Configure DMA request hdma_memtomem_dma2_stream0 on DMA2_Stream0 */
  hdma_memtomem_dma2_stream0.Instance = DMA2_Stream0;
  hdma_memtomem_dma2_stream0.Init.Channel = DMA_CHANNEL_0;
  hdma_memtomem_dma2_stream0.Init.Direction = DMA_MEMORY_TO_MEMORY;
  hdma_memtomem_dma2_stream0.Init.PeriphInc = DMA_PINC_ENABLE;
  hdma_memtomem_dma2_stream0.Init.MemInc = DMA_MINC_DISABLE;
  hdma_memtomem_dma2_stream0.Init.PeriphDataAlignment = DMA_PDATAALIGN_BYTE;
  hdma_memtomem_dma2_stream0.Init.MemDataAlignment = DMA_MDATAALIGN_BYTE;
  hdma_memtomem_dma2_stream0.Init.Mode = DMA_NORMAL;
  hdma_memtomem_dma2_stream0.Init.Priority = DMA_PRIORITY_LOW;
  hdma_memtomem_dma2_stream0.Init.FIFOMode = DMA_FIFOMODE_ENABLE;
  hdma_memtomem_dma2_stream0.Init.FIFOThreshold = DMA_FIFO_THRESHOLD_FULL;
  hdma_memtomem_dma2_stream0.Init.MemBurst = DMA_MBURST_SINGLE;
  hdma_memtomem_dma2_stream0.Init.PeriphBurst = DMA_PBURST_SINGLE;
  if (HAL_DMA_Init(&hdma_memtomem_dma2_stream0) != HAL_OK)
  {
    Error_Handler( );
  }

  /* DMA interrupt init */
  /* DMA1_Stream0_IRQn interrupt configuration */
  HAL_NVIC_SetPriority(DMA1_Stream0_IRQn, 6, 0);
  HAL_NVIC_EnableIRQ(DMA1_Stream0_IRQn);
  /* DMA1_Stream5_IRQn interrupt configuration */
  HAL_NVIC_SetPriority(DMA1_Stream5_IRQn, 6, 0);
  HAL_NVIC_EnableIRQ(DMA1_Stream5_IRQn);
  /* DMA2_Stream1_IRQn interrupt configuration */
  HAL_NVIC_SetPriority(DMA2_Stream1_IRQn, 15, 0);
  HAL_NVIC_EnableIRQ(DMA2_Stream1_IRQn);
  /* DMA2_Stream2_IRQn interrupt configuration */
  HAL_NVIC_SetPriority(DMA2_Stream2_IRQn, 15, 0);
  HAL_NVIC_EnableIRQ(DMA2_Stream2_IRQn);
  /* DMA2_Stream4_IRQn interrupt configuration */
  HAL_NVIC_SetPriority(DMA2_Stream4_IRQn, 15, 0);
  HAL_NVIC_EnableIRQ(DMA2_Stream4_IRQn);

}

static void MX_GPIO_Init(void)
{
  GPIO_InitTypeDef GPIO_InitStruct = {0};

  /* GPIO Ports Clock Enable */
  __HAL_RCC_GPIOE_CLK_ENABLE();
  __HAL_RCC_GPIOC_CLK_ENABLE();
  __HAL_RCC_GPIOH_CLK_ENABLE();
  __HAL_RCC_GPIOA_CLK_ENABLE();
  __HAL_RCC_GPIOB_CLK_ENABLE();
  __HAL_RCC_GPIOD_CLK_ENABLE();

  /*Configure GPIO pin Output Level */
  HAL_GPIO_WritePin(GPIOE, DMR_SPI_CS_Pin|C6000_PWD_Pin, GPIO_PIN_SET);

  /*Configure GPIO pin Output Level */
  HAL_GPIO_WritePin(GPIOE, DMR_SPI_CLK_Pin|DMR_SPI_MOSI_Pin|LED_GREEN_Pin|LED_RED_Pin, GPIO_PIN_RESET);

  /*Configure GPIO pin Output Level */
  HAL_GPIO_WritePin(GPIOA, R5_U_SW_Pin|R5_V_SW_Pin|KEYPAD_ROW0_Pin|PWR_SW_Pin
                          |MICPWR_SW_Pin, GPIO_PIN_RESET);

  /*Configure GPIO pin Output Level */
  HAL_GPIO_WritePin(GPIOC, PA_EN_2_Pin|PA_EN_1_Pin|PA_SEL_SW_Pin|BEEP_PWM_Pin, GPIO_PIN_RESET);

  /*Configure GPIO pin Output Level */
  HAL_GPIO_WritePin(GPIOB, V_SPI_CS_Pin|SPK_MUTE_Pin|AUDIO_AMP_EN_Pin, GPIO_PIN_SET);

  /*Configure GPIO pin Output Level */
  HAL_GPIO_WritePin(GPIOD, LCD_BKLIGHT_Pin|KEYPAD_ROW1_Pin|KEYPAD_ROW2_Pin, GPIO_PIN_RESET);

  /*Configure GPIO pin Output Level */
  HAL_GPIO_WritePin(GPIOD, RX_AUDIO_MUX_Pin|SPI_Flash_CS_Pin, GPIO_PIN_SET);

  /*Configure GPIO pin Output Level */
  HAL_GPIO_WritePin(CTC_DCS_PWM_GPIO_Port, CTC_DCS_PWM_Pin, GPIO_PIN_SET);

  /*Configure GPIO pins : DMR_SPI_CS_Pin DMR_SPI_CLK_Pin DMR_SPI_MOSI_Pin C6000_PWD_Pin
                           LED_GREEN_Pin LED_RED_Pin */
  GPIO_InitStruct.Pin = DMR_SPI_CS_Pin|DMR_SPI_CLK_Pin|DMR_SPI_MOSI_Pin|C6000_PWD_Pin
                          |LED_GREEN_Pin|LED_RED_Pin;
  GPIO_InitStruct.Mode = GPIO_MODE_OUTPUT_PP;
  GPIO_InitStruct.Pull = GPIO_NOPULL;
  GPIO_InitStruct.Speed = GPIO_SPEED_FREQ_LOW;
  HAL_GPIO_Init(GPIOE, &GPIO_InitStruct);

  /*Configure GPIO pin : DMR_SPI_MISO_Pin */
  GPIO_InitStruct.Pin = DMR_SPI_MISO_Pin;
  GPIO_InitStruct.Mode = GPIO_MODE_INPUT;
  GPIO_InitStruct.Pull = GPIO_NOPULL;
  HAL_GPIO_Init(DMR_SPI_MISO_GPIO_Port, &GPIO_InitStruct);

  /*Configure GPIO pins : TIME_SLOT_INTER_Pin SYS_INTER_Pin RF_TX_INTER_Pin */
  GPIO_InitStruct.Pin = TIME_SLOT_INTER_Pin|SYS_INTER_Pin|RF_TX_INTER_Pin;
  GPIO_InitStruct.Mode = GPIO_MODE_IT_FALLING;
  GPIO_InitStruct.Pull = GPIO_NOPULL;
  HAL_GPIO_Init(GPIOC, &GPIO_InitStruct);

  /*Configure GPIO pins : R5_U_SW_Pin R5_V_SW_Pin KEYPAD_ROW0_Pin PWR_SW_Pin
                           MICPWR_SW_Pin */
  GPIO_InitStruct.Pin = R5_U_SW_Pin|R5_V_SW_Pin|KEYPAD_ROW0_Pin|PWR_SW_Pin
                          |MICPWR_SW_Pin;
  GPIO_InitStruct.Mode = GPIO_MODE_OUTPUT_PP;
  GPIO_InitStruct.Pull = GPIO_NOPULL;
  GPIO_InitStruct.Speed = GPIO_SPEED_FREQ_LOW;
  HAL_GPIO_Init(GPIOA, &GPIO_InitStruct);

  /*Configure GPIO pins : PA_EN_2_Pin PA_EN_1_Pin PA_SEL_SW_Pin BEEP_PWM_Pin */
  GPIO_InitStruct.Pin = PA_EN_2_Pin|PA_EN_1_Pin|PA_SEL_SW_Pin|BEEP_PWM_Pin;
  GPIO_InitStruct.Mode = GPIO_MODE_OUTPUT_PP;
  GPIO_InitStruct.Pull = GPIO_NOPULL;
  GPIO_InitStruct.Speed = GPIO_SPEED_FREQ_LOW;
  HAL_GPIO_Init(GPIOC, &GPIO_InitStruct);

  /*Configure GPIO pins : LCD_D4_Pin LCD_D5_Pin LCD_D6_Pin LCD_D7_Pin */
  GPIO_InitStruct.Pin = LCD_D4_Pin|LCD_D5_Pin|LCD_D6_Pin|LCD_D7_Pin;
  GPIO_InitStruct.Mode = GPIO_MODE_INPUT;
  GPIO_InitStruct.Pull = GPIO_PULLDOWN;
  HAL_GPIO_Init(GPIOE, &GPIO_InitStruct);

  /*Configure GPIO pins : PTT_Pin PTT_EXTERNAL_Pin ROTARY_SW_A_Pin */
  GPIO_InitStruct.Pin = PTT_Pin|PTT_EXTERNAL_Pin|ROTARY_SW_A_Pin;
  GPIO_InitStruct.Mode = GPIO_MODE_INPUT;
  GPIO_InitStruct.Pull = GPIO_PULLUP;
  HAL_GPIO_Init(GPIOE, &GPIO_InitStruct);

  /*Configure GPIO pin : ROTARY_SW_B_Pin */
  GPIO_InitStruct.Pin = ROTARY_SW_B_Pin;
  GPIO_InitStruct.Mode = GPIO_MODE_IT_RISING_FALLING;
  GPIO_InitStruct.Pull = GPIO_PULLUP;
  HAL_GPIO_Init(ROTARY_SW_B_GPIO_Port, &GPIO_InitStruct);

  /*Configure GPIO pins : V_SPI_CS_Pin SPK_MUTE_Pin AUDIO_AMP_EN_Pin */
  GPIO_InitStruct.Pin = V_SPI_CS_Pin|SPK_MUTE_Pin|AUDIO_AMP_EN_Pin;
  GPIO_InitStruct.Mode = GPIO_MODE_OUTPUT_PP;
  GPIO_InitStruct.Pull = GPIO_NOPULL;
  GPIO_InitStruct.Speed = GPIO_SPEED_FREQ_LOW;
  HAL_GPIO_Init(GPIOB, &GPIO_InitStruct);

  /*Configure GPIO pins : LCD_BKLIGHT_Pin RX_AUDIO_MUX_Pin KEYPAD_ROW1_Pin KEYPAD_ROW2_Pin
                           SPI_Flash_CS_Pin */
  GPIO_InitStruct.Pin = LCD_BKLIGHT_Pin|RX_AUDIO_MUX_Pin|KEYPAD_ROW1_Pin|KEYPAD_ROW2_Pin
                          |SPI_Flash_CS_Pin;
  GPIO_InitStruct.Mode = GPIO_MODE_OUTPUT_PP;
  GPIO_InitStruct.Pull = GPIO_NOPULL;
  GPIO_InitStruct.Speed = GPIO_SPEED_FREQ_LOW;
  HAL_GPIO_Init(GPIOD, &GPIO_InitStruct);

  /*Configure GPIO pins : LCD_RS_Pin LCD_RST_Pin LCD_RD_Pin LCD_WR_Pin
                           LCD_CS_Pin */
  GPIO_InitStruct.Pin = LCD_RS_Pin|LCD_RST_Pin|LCD_RD_Pin|LCD_WR_Pin
                          |LCD_CS_Pin;
  GPIO_InitStruct.Mode = GPIO_MODE_INPUT;
  GPIO_InitStruct.Pull = GPIO_NOPULL;
  HAL_GPIO_Init(GPIOD, &GPIO_InitStruct);

  /*Configure GPIO pins : LCD_D0_Pin LCD_D1_Pin LCD_D2_Pin LCD_D3_Pin */
  GPIO_InitStruct.Pin = LCD_D0_Pin|LCD_D1_Pin|LCD_D2_Pin|LCD_D3_Pin;
  GPIO_InitStruct.Mode = GPIO_MODE_INPUT;
  GPIO_InitStruct.Pull = GPIO_PULLDOWN;
  HAL_GPIO_Init(GPIOD, &GPIO_InitStruct);

  /*Configure GPIO pin : CTC_DCS_PWM_Pin */
  GPIO_InitStruct.Pin = CTC_DCS_PWM_Pin;
  GPIO_InitStruct.Mode = GPIO_MODE_OUTPUT_OD;
  GPIO_InitStruct.Pull = GPIO_NOPULL;
  GPIO_InitStruct.Speed = GPIO_SPEED_FREQ_LOW;
  HAL_GPIO_Init(CTC_DCS_PWM_GPIO_Port, &GPIO_InitStruct);

  /* EXTI interrupt init*/
  HAL_NVIC_SetPriority(EXTI0_IRQn, 5, 0);
  HAL_NVIC_EnableIRQ(EXTI0_IRQn);

  HAL_NVIC_SetPriority(EXTI1_IRQn, 5, 0);
  HAL_NVIC_EnableIRQ(EXTI1_IRQn);

  HAL_NVIC_SetPriority(EXTI2_IRQn, 5, 0);
  HAL_NVIC_EnableIRQ(EXTI2_IRQn);

  HAL_NVIC_SetPriority(EXTI15_10_IRQn, 6, 0);
  HAL_NVIC_EnableIRQ(EXTI15_10_IRQn);

}

void StartDefaultTask(void *argument)
{
  /* init code for USB_DEVICE */

  /* USER CODE BEGIN 5 */
	applicationMainTask();
  /* USER CODE END 5 */
}

void HAL_TIM_PeriodElapsedCallback(TIM_HandleTypeDef *htim)
{
  if (htim->Instance == TIM14) {
    HAL_IncTick();
  }
}

void Error_Handler(void)
{
}
